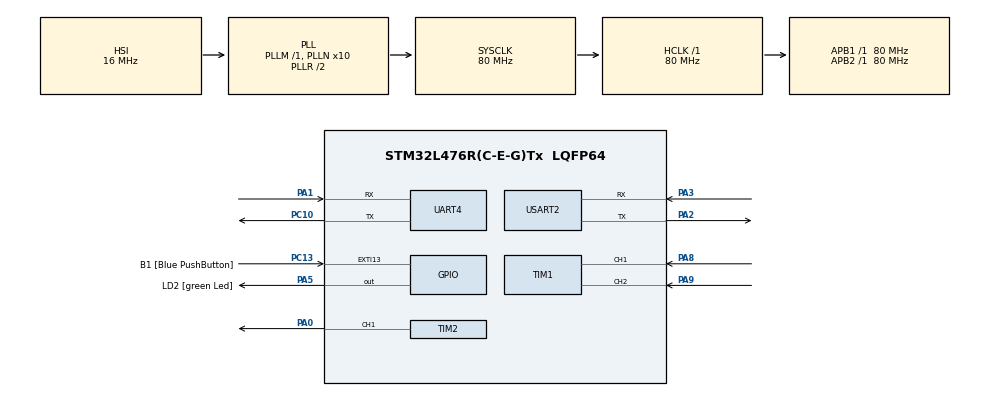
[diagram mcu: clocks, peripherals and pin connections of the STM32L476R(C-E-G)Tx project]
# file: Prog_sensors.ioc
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Dma.Request0=UART4_RX
Dma.UART4_RX.0.Direction=DMA_PERIPH_TO_MEMORY
Dma.UART4_RX.0.Instance=DMA2_Channel5
Dma.UART4_RX.0.MemDataAlignment=DMA_MDATAALIGN_BYTE
Dma.UART4_RX.0.MemInc=DMA_MINC_ENABLE
Dma.UART4_RX.0.Mode=DMA_CIRCULAR
Dma.UART4_RX.0.PeriphDataAlignment=DMA_PDATAALIGN_BYTE
Dma.UART4_RX.0.PeriphInc=DMA_PINC_DISABLE
Dma.UART4_RX.0.Priority=DMA_PRIORITY_MEDIUM
FREERTOS.INCLUDE_uxTaskGetStackHighWaterMark=1
FREERTOS.INCLUDE_uxTaskGetStackHighWaterMark2=0
FREERTOS.Tasks01=defaultTask,0,128,StartDefaultTask,Default,NULL,Dynamic,NULL,NULL
FREERTOS.configCHECK_FOR_STACK_OVERFLOW=2
FREERTOS.configGENERATE_RUN_TIME_STATS=1
FREERTOS.configRECORD_STACK_HIGH_ADDRESS=1
FREERTOS.configTOTAL_HEAP_SIZE=2000
FREERTOS.configUSE_MALLOC_FAILED_HOOK=1
FREERTOS.configUSE_STATS_FORMATTING_FUNCTIONS=1
FREERTOS.configUSE_TRACE_FACILITY=1
Mcu.Family=STM32L4
Mcu.Name=STM32L476R(C-E-G)Tx
Mcu.Package=LQFP64
NVIC.DMA2_Channel5_IRQn=true\:5\:0\:false\:false\:true\:true\:false\:true\:true
NVIC.EXTI15_10_IRQn=true\:5\:0\:false\:false\:true\:true\:true\:true\:true
NVIC.PriorityGroup=NVIC_PRIORITYGROUP_4
NVIC.TIM6_DAC_IRQn=true\:5\:0\:false\:false\:true\:true\:true\:true\:true
NVIC.TIM7_IRQn=true\:15\:0\:false\:false\:true\:false\:false\:true\:true
NVIC.TimeBase=TIM7_IRQn
NVIC.TimeBaseIP=TIM7
PA0.Signal=S_TIM2_CH1
PA1.Mode=Asynchronous
PA1.Signal=UART4_RX
PA13\ (JTMS-SWDIO).GPIO_Label=TMS
PA13\ (JTMS-SWDIO).Mode=Serial_Wire
PA13\ (JTMS-SWDIO).Signal=SYS_JTMS-SWDIO
PA14\ (JTCK-SWCLK).GPIO_Label=TCK
PA14\ (JTCK-SWCLK).Mode=Serial_Wire
PA14\ (JTCK-SWCLK).Signal=SYS_JTCK-SWCLK
PA2.Mode=Asynchronous
PA2.Signal=USART2_TX
PA3.Mode=Asynchronous
PA3.Signal=USART2_RX
PA5.GPIO_Label=LD2 [green Led]
PA5.GPIO_ModeDefaultOutputPP=GPIO_MODE_OUTPUT_PP
PA5.GPIO_PuPd=GPIO_NOPULL
PA5.GPIO_Speed=GPIO_SPEED_FREQ_LOW
PA5.Signal=GPIO_Output
PA8.Signal=S_TIM1_CH1
PA9.Signal=S_TIM1_CH2
PB3\ (JTDO-TRACESWO).GPIO_Label=SWO
PB3\ (JTDO-TRACESWO).Signal=SYS_JTDO-SWO
PC10.Mode=Asynchronous
PC10.Signal=UART4_TX
PC13.GPIO_Label=B1 [Blue PushButton]
PC13.GPIO_ModeDefaultEXTI=GPIO_MODE_IT_FALLING
PC13.GPIO_PuPd=GPIO_NOPULL
PC13.Signal=GPXTI13
PC14-OSC32_IN\ (PC14).Mode=LSE-External-Oscillator
PC14-OSC32_IN\ (PC14).Signal=RCC_OSC32_IN
PC15-OSC32_OUT\ (PC15).Mode=LSE-External-Oscillator
PC15-OSC32_OUT\ (PC15).Signal=RCC_OSC32_OUT
PH0-OSC_IN\ (PH0).Signal=RCC_OSC_IN
PH1-OSC_OUT\ (PH1).Signal=RCC_OSC_OUT
ProjectManager.HeapSize=0x200
ProjectManager.StackSize=0x400
ProjectManager.TargetToolchain=STM32CubeIDE
RCC.ADCFreq_Value=64000000
RCC.AHBFreq_Value=80000000
RCC.APB1Freq_Value=80000000
RCC.APB1TimFreq_Value=80000000
RCC.APB2Freq_Value=80000000
RCC.APB2TimFreq_Value=80000000
RCC.CortexFreq_Value=80000000
RCC.HCLKFreq_Value=80000000
RCC.HSE_VALUE=8000000
RCC.HSI_VALUE=16000000
RCC.MSI_VALUE=4000000
RCC.PLLN=10
RCC.PLLSourceVirtual=RCC_PLLSOURCE_HSI
RCC.PREFETCH_ENABLE=1
RCC.SYSCLKFreq_VALUE=80000000
RCC.SYSCLKSource=RCC_SYSCLKSOURCE_PLLCLK
RCC.USBFreq_Value=64000000
RCC.VCOOutputFreq_Value=160000000
SH.S_TIM1_CH1.0=TIM1_CH1,Encoder_Interface
SH.S_TIM1_CH2.0=TIM1_CH2,Encoder_Interface
SH.S_TIM2_CH1.0=TIM2_CH1,PWM Generation1 CH1
TIM1.EncoderMode=TIM_ENCODERMODE_TI12
TIM2.Channel-PWM\ Generation1\ CH1=TIM_CHANNEL_1
TIM2.Period=100-1
TIM2.Prescaler=80-1
TIM6.Period=60000
TIM6.Prescaler=3000-1
USART2.VirtualMode-Asynchronous=VM_ASYNC
VP_FREERTOS_VS_CMSIS_V1.Mode=CMSIS_V1
VP_SYS_VS_tim7.Mode=TIM7
VP_TIM6_VS_ClockSourceINT.Mode=Enable_Timer
board=NUCLEO-L476RG

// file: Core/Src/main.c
/* USER CODE BEGIN Header */
/**
 ******************************************************************************
 * @file           : main.c
 * @brief          : Main program body
 ******************************************************************************
 * @attention
 *
 * Copyright (c) 2025 STMicroelectronics.
 * All rights reserved.
 *
 * This software is licensed under terms that can be found in the LICENSE file
 * in the root directory of this software component.
 * If no LICENSE file comes with this software, it is provided AS-IS.
 *
 ******************************************************************************
 */
/* USER CODE END Header */
#include "main.h"
#include "cmsis_os.h"
#include "dma.h"
#include "tim.h"
#include "usart.h"
#include "gpio.h"

/* USER CODE BEGIN Includes */
#include "stdio.h"
/* USER CODE END Includes */

void SystemClock_Config(void);
void MX_FREERTOS_Init(void);

/* USER CODE BEGIN 0 */
int __io_putchar(int chr){
	HAL_UART_Transmit(&huart2, (uint8_t*) &chr, 1, HAL_MAX_DELAY);
	return chr;
}

//protection mémoire

void vApplicationMallocFailedHook(void)
{
    printf("Malloc failed !\r\n"); //n'arrive pas à créé une task (pas de place)
    taskDISABLE_INTERRUPTS();
    for( ;; );
}

void vApplicationStackOverflowHook(TaskHandle_t xTask, char *pcTaskName)
{
    printf("Stack overflow in task %s\r\n", pcTaskName); //Stack overflow
    Error_Handler();
}

/* USER CODE END 0 */

int main(void)
{

  /* MCU Configuration--------------------------------------------------------*/

  /* Reset of all peripherals, Initializes the Flash interface and the Systick. */
  HAL_Init();

  /* Configure the system clock */
  SystemClock_Config();

  /* Initialize all configured peripherals */
  MX_GPIO_Init();
  MX_DMA_Init();
  MX_TIM2_Init();
  MX_UART4_Init();
  MX_USART2_UART_Init();
  MX_TIM6_Init();
  MX_TIM1_Init();
  /* USER CODE BEGIN 2 */
	LIDAR_Init();
	ENC_Init();

	vTaskStartScheduler();	//Démarre l'os => boucle infinie => rien ne s'exécutera après cette ligne

  /* USER CODE END 2 */

  /* Call init function for freertos objects (in cmsis_os2.c) */
  MX_FREERTOS_Init();

  /* Start scheduler */
  osKernelStart();

  /* We should never get here as control is now taken by the scheduler */

  /* Infinite loop */
  /* USER CODE BEGIN WHILE */
	while (1)
	{
		//		LIDAR_While();
    /* USER CODE END WHILE */

	}
}

void SystemClock_Config(void)
{
  RCC_OscInitTypeDef RCC_OscInitStruct = {0};
  RCC_ClkInitTypeDef RCC_ClkInitStruct = {0};

  /** Configure the main internal regulator output voltage
  */
  if (HAL_PWREx_ControlVoltageScaling(PWR_REGULATOR_VOLTAGE_SCALE1) != HAL_OK)
  {
    Error_Handler();
  }

  /** Initializes the RCC Oscillators according to the specified parameters
  * in the RCC_OscInitTypeDef structure.
  */
  RCC_OscInitStruct.OscillatorType = RCC_OSCILLATORTYPE_HSI;
  RCC_OscInitStruct.HSIState = RCC_HSI_ON;
  RCC_OscInitStruct.HSICalibrationValue = RCC_HSICALIBRATION_DEFAULT;
  RCC_OscInitStruct.PLL.PLLState = RCC_PLL_ON;
  RCC_OscInitStruct.PLL.PLLSource = RCC_PLLSOURCE_HSI;
  RCC_OscInitStruct.PLL.PLLM = 1;
  RCC_OscInitStruct.PLL.PLLN = 10;
  RCC_OscInitStruct.PLL.PLLP = RCC_PLLP_DIV7;
  RCC_OscInitStruct.PLL.PLLQ = RCC_PLLQ_DIV2;
  RCC_OscInitStruct.PLL.PLLR = RCC_PLLR_DIV2;
  if (HAL_RCC_OscConfig(&RCC_OscInitStruct) != HAL_OK)
  {
    Error_Handler();
  }

  /** Initializes the CPU, AHB and APB buses clocks
  */
  RCC_ClkInitStruct.ClockType = RCC_CLOCKTYPE_HCLK|RCC_CLOCKTYPE_SYSCLK
                              |RCC_CLOCKTYPE_PCLK1|RCC_CLOCKTYPE_PCLK2;
  RCC_ClkInitStruct.SYSCLKSource = RCC_SYSCLKSOURCE_PLLCLK;
  RCC_ClkInitStruct.AHBCLKDivider = RCC_SYSCLK_DIV1;
  RCC_ClkInitStruct.APB1CLKDivider = RCC_HCLK_DIV1;
  RCC_ClkInitStruct.APB2CLKDivider = RCC_HCLK_DIV1;

  if (HAL_RCC_ClockConfig(&RCC_ClkInitStruct, FLASH_LATENCY_4) != HAL_OK)
  {
    Error_Handler();
  }
}

void HAL_TIM_PeriodElapsedCallback(TIM_HandleTypeDef *htim)
{
  if (htim->Instance == TIM7)
  {
    HAL_IncTick();
  }
  /* USER CODE BEGIN Callback 1 */
  enc_HAL_TIM_PeriodElapsedCallback(htim);

  /* USER CODE END Callback 1 */
}

void Error_Handler(void)
{
	__disable_irq();
	while (1)
	{
	}
}

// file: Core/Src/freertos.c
/* USER CODE BEGIN Header */
/**
  ******************************************************************************
  * File Name          : freertos.c
  * Description        : Code for freertos applications
  ******************************************************************************
  * @attention
  *
  * Copyright (c) 2025 STMicroelectronics.
  * All rights reserved.
  *
  * This software is licensed under terms that can be found in the LICENSE file
  * in the root directory of this software component.
  * If no LICENSE file comes with this software, it is provided AS-IS.
  *
  ******************************************************************************
  */
/* USER CODE END Header */

#include "FreeRTOS.h"
#include "task.h"
#include "main.h"
#include "cmsis_os.h"

osThreadId defaultTaskHandle;

void StartDefaultTask(void const * argument);

void MX_FREERTOS_Init(void); /* (MISRA C 2004 rule 8.1) */

/* GetIdleTaskMemory prototype (linked to static allocation support) */
void vApplicationGetIdleTaskMemory( StaticTask_t **ppxIdleTaskTCBBuffer, StackType_t **ppxIdleTaskStackBuffer, uint32_t *pulIdleTaskStackSize );

/* Hook prototypes */
void configureTimerForRunTimeStats(void);
unsigned long getRunTimeCounterValue(void);
void vApplicationStackOverflowHook(xTaskHandle xTask, signed char *pcTaskName);
void vApplicationMallocFailedHook(void);

/* USER CODE BEGIN 1 */
/* Functions needed when configGENERATE_RUN_TIME_STATS is on */
__weak void configureTimerForRunTimeStats(void)
{

}

__weak unsigned long getRunTimeCounterValue(void)
{
return 0;
}
/* USER CODE END 1 */

/* USER CODE BEGIN 4 */
__weak void vApplicationStackOverflowHook(xTaskHandle xTask, signed char *pcTaskName)
{
   /* Run time stack overflow checking is performed if
   configCHECK_FOR_STACK_OVERFLOW is defined to 1 or 2. This hook function is
   called if a stack overflow is detected. */
}
/* USER CODE END 4 */

/* USER CODE BEGIN 5 */
__weak void vApplicationMallocFailedHook(void)
{
   /* vApplicationMallocFailedHook() will only be called if
   configUSE_MALLOC_FAILED_HOOK is set to 1 in FreeRTOSConfig.h. It is a hook
   function that will get called if a call to pvPortMalloc() fails.
   pvPortMalloc() is called internally by the kernel whenever a task, queue,
   timer or semaphore is created. It is also called by various parts of the
   demo application. If heap_1.c or heap_2.c are used, then the size of the
   heap available to pvPortMalloc() is defined by configTOTAL_HEAP_SIZE in
   FreeRTOSConfig.h, and the xPortGetFreeHeapSize() API function can be used
   to query the size of free heap space that remains (although it does not
   provide information on how the remaining heap might be fragmented). */
}
/* USER CODE END 5 */

/* USER CODE BEGIN GET_IDLE_TASK_MEMORY */
static StaticTask_t xIdleTaskTCBBuffer;
static StackType_t xIdleStack[configMINIMAL_STACK_SIZE];

void vApplicationGetIdleTaskMemory( StaticTask_t **ppxIdleTaskTCBBuffer, StackType_t **ppxIdleTaskStackBuffer, uint32_t *pulIdleTaskStackSize )
{
  *ppxIdleTaskTCBBuffer = &xIdleTaskTCBBuffer;
  *ppxIdleTaskStackBuffer = &xIdleStack[0];
  *pulIdleTaskStackSize = configMINIMAL_STACK_SIZE;
  /* place for user code */
}
/* USER CODE END GET_IDLE_TASK_MEMORY */

void MX_FREERTOS_Init(void) {

  /* Create the thread(s) */
  /* definition and creation of defaultTask */
  osThreadDef(defaultTask, StartDefaultTask, osPriorityNormal, 0, 128);
  defaultTaskHandle = osThreadCreate(osThread(defaultTask), NULL);

}

void StartDefaultTask(void const * argument)
{
  for(;;)
  {
    osDelay(1);
  }
}
